# CH569 register map
Vendor: WCH Ltd.; File version: 1.1
Registers are 32-bit, read-write, reset 0x0 unless marked. A register's access mark holds for its fields unless they carry their own. Offsets are from the block's base; [hi:lo] are bit positions; {n}, {i} and the like mark numbered series.

## SYS
Base 0x40001000
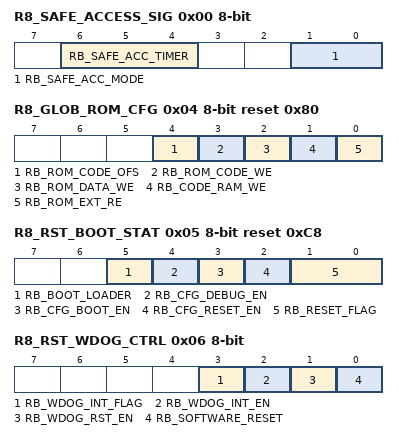
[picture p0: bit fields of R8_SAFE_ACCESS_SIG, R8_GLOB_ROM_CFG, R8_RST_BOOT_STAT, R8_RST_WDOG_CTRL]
0x00 R8_SAFE_ACCESS_SIG 8-bit — safe accessing sign register
  [6:4] RB_SAFE_ACC_TIMER ro — safe accessing timer bit mask
  [1:0] RB_SAFE_ACC_MODE ro — current safe accessing mode
0x01 R8_CHIP_ID 8-bit ro reset 0x69 — chip ID register
  [7:0] R8_CHIP_ID — chip ID
0x02 R8_SAFE_ACCESS_ID 8-bit ro reset 0x2 — safe accessing ID register
  [7:0] R8_SAFE_ACCESS_ID — safe accessing ID
0x03 R8_WDOG_COUNT 8-bit — watch-dog count register
  [7:0] R8_WDOG_COUNT — watch-dog count
0x04 R8_GLOB_ROM_CFG 8-bit access per field reset 0x80 — flash ROM configuration register
  [4] RB_ROM_CODE_OFS rw — Config the start offset address of user code in Flash
  [3] RB_ROM_CODE_WE rw — enable flash ROM code_data area being erase/write
  [2] RB_ROM_DATA_WE rw — enable flash ROM data area being erase/write
  [1] RB_CODE_RAM_WE rw — enable code RAM being write
  [0] RB_ROM_EXT_RE ro — enable flash ROM being read by external programmer
0x05 R8_RST_BOOT_STAT 8-bit ro reset 0xC8 — reset status and boot/debug status
  [5] RB_BOOT_LOADER — indicate boot loader status
  [4] RB_CFG_DEBUG_EN — debug enable status
  [3] RB_CFG_BOOT_EN — boot-loader enable status
  [2] RB_CFG_RESET_EN — manual reset input enable status
  [1:0] RB_RESET_FLAG — recent reset flag
0x06 R8_RST_WDOG_CTRL 8-bit access per field — reset and watch-dog control
  [3] RB_WDOG_INT_FLAG rw — watch-dog timer overflow interrupt flag
  [2] RB_WDOG_INT_EN rw — watch-dog interrupt enable or INT_ID_WDOG interrupt source selection: 0=software interrupt
  [1] RB_WDOG_RST_EN rw — enable watch-dog reset if watch-dog timer overflow: 0=as timer only, 1=enable reset if timer overflow
  [0] RB_SOFTWARE_RESET wo — global software reset
0x07 R8_GLOB_RESET_KEEP 8-bit — value keeper during global reset
0x08 R8_CLK_PLL_DIV 8-bit reset 0x42 — output clock divider from PLL
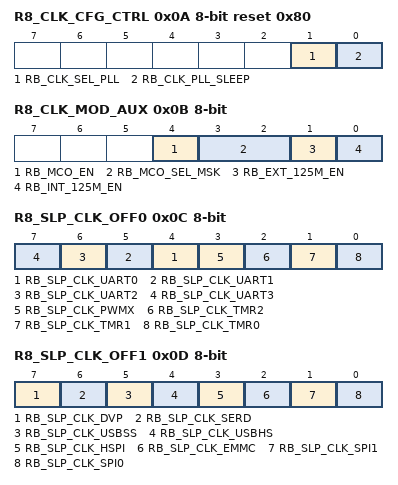
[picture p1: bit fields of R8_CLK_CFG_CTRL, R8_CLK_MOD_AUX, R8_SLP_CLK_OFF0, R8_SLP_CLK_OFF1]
0x0A R8_CLK_CFG_CTRL 8-bit reset 0x80 — clock control
  [1] RB_CLK_SEL_PLL — clock source selection
  [0] RB_CLK_PLL_SLEEP — PLL sleep control
0x0B R8_CLK_MOD_AUX 8-bit — clock mode aux register
  [4] RB_MCO_EN — MCO output enable
  [3:2] RB_MCO_SEL_MSK — MCO output selection
  [1] RB_EXT_125M_EN — clock from pin_PA[16]
  [0] RB_INT_125M_EN — clock from USB_PHY PCLK(125MHz)
0x0C R8_SLP_CLK_OFF0 8-bit — sleep clock off control byte 0
  [n+4] RB_SLP_CLK_UART{n} (n=0..3) — sleep UART{n} clock
  [3] RB_SLP_CLK_PWMX — sleep PWMX clock
  [2] RB_SLP_CLK_TMR2 — sleep TMR2 clock
  [1] RB_SLP_CLK_TMR1 — sleep TMR1 clock
  [0] RB_SLP_CLK_TMR0 — sleep TMR0 clock
0x0D R8_SLP_CLK_OFF1 8-bit access per field — sleep clock off control byte 1
  [7] RB_SLP_CLK_DVP ro — sleep DVP clock
  [6] RB_SLP_CLK_SERD rw — sleep SERD clock
  [5] RB_SLP_CLK_USBSS rw — sleep USBSS clock
  [4] RB_SLP_CLK_USBHS rw — sleep USBHS clock
  [3] RB_SLP_CLK_HSPI rw — sleep HSPI clock
  [2] RB_SLP_CLK_EMMC rw — sleep EMMC clock
  [1] RB_SLP_CLK_SPI1 rw — sleep SPI1 clock
  [0] RB_SLP_CLK_SPI0 rw — sleep SPI0 clock
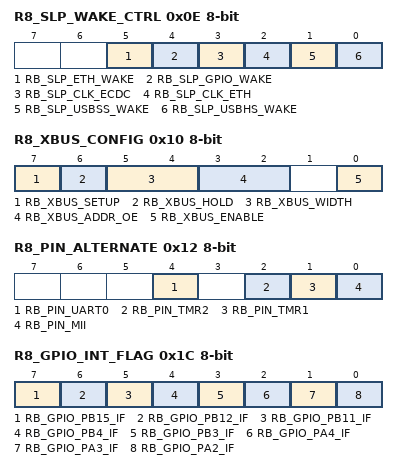
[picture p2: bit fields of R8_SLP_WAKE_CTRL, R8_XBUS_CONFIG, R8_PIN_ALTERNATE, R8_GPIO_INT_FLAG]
0x0E R8_SLP_WAKE_CTRL 8-bit — wake control
  [5] RB_SLP_ETH_WAKE — enable Eth waking
  [4] RB_SLP_GPIO_WAKE — enable GPIO waking
  [3] RB_SLP_CLK_ECDC — sleep ECDC clock
  [2] RB_SLP_CLK_ETH — sleep ETH clock
  [1] RB_SLP_USBSS_WAKE — enable USBSS waking
  [0] RB_SLP_USBHS_WAKE — enable USBHS waking
0x0F R8_SLP_POWER_CTRL 8-bit — power control
  [0] RB_SLP_USBHS_PWRDN — enable USBHS power down
0x10 R8_XBUS_CONFIG 8-bit — external bus configuration
  [7] RB_XBUS_SETUP — external bus setup time
  [6] RB_XBUS_HOLD — external bus hold time
  [5:4] RB_XBUS_WIDTH — external bus access pulse width
  [3:2] RB_XBUS_ADDR_OE — external bus address output enable
  [0] RB_XBUS_ENABLE — external bus enable
0x12 R8_PIN_ALTERNATE 8-bit — alternate pin control
  [4] RB_PIN_UART0 — RXD0/TXD0 alternate pin enable
  [2] RB_PIN_TMR2 — TMR2 alternate pin enable
  [1] RB_PIN_TMR1 — TMR1 alternate pin enable
  [0] RB_PIN_MII — ETH mii interface selection
0x1C R8_GPIO_INT_FLAG 8-bit — GPIO interrupt control
  [7] RB_GPIO_PB15_IF — PB15 pin interrupt flag
  [6] RB_GPIO_PB12_IF — PB12 pin interrupt flag
  [5] RB_GPIO_PB11_IF — PB11 pin interrupt flag
  [4] RB_GPIO_PB4_IF — PB4 pin interrupt flag
  [3] RB_GPIO_PB3_IF — PB3 pin interrupt flag
  [2] RB_GPIO_PA4_IF — PA4 pin interrupt flag
  [1] RB_GPIO_PA3_IF — PA3 pin interrupt flag
  [0] RB_GPIO_PA2_IF — PA2 pin interrupt flag
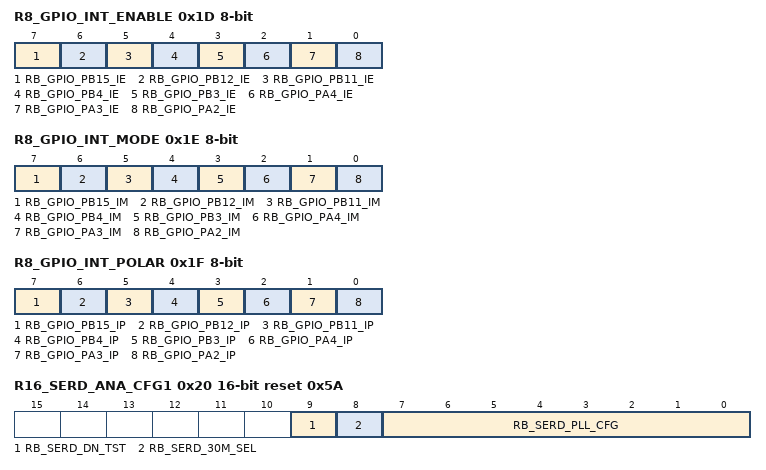
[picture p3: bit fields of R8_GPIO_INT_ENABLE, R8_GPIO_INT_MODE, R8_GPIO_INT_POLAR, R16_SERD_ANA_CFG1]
0x1D R8_GPIO_INT_ENABLE 8-bit — GPIO interrupt enable
  [7] RB_GPIO_PB15_IE — PB15 pin interrupt enable
  [6] RB_GPIO_PB12_IE — PB12 pin interrupt enable
  [5] RB_GPIO_PB11_IE — PB11 pin interrupt enable
  [4] RB_GPIO_PB4_IE — PB4 pin interrupt enable
  [3] RB_GPIO_PB3_IE — PB3 pin interrupt enable
  [2] RB_GPIO_PA4_IE — PA4 pin interrupt enable
  [1] RB_GPIO_PA3_IE — PA3 pin interrupt enable
  [0] RB_GPIO_PA2_IE — PA2 pin interrupt enable
0x1E R8_GPIO_INT_MODE 8-bit — GPIO interrupt mode
  [7] RB_GPIO_PB15_IM — PB15 pin interrupt mode
  [6] RB_GPIO_PB12_IM — PB12 pin interrupt mode
  [5] RB_GPIO_PB11_IM — PB11 pin interrupt mode
  [4] RB_GPIO_PB4_IM — PB4 pin interrupt mode
  [3] RB_GPIO_PB3_IM — PB3 pin interrupt mode
  [2] RB_GPIO_PA4_IM — PA4 pin interrupt mode
  [1] RB_GPIO_PA3_IM — PA3 pin interrupt mode
  [0] RB_GPIO_PA2_IM — PA2 pin interrupt mode
0x1F R8_GPIO_INT_POLAR 8-bit — GPIO interrupt polarity
  [7] RB_GPIO_PB15_IP — PB15 pin interrupt mode
  [6] RB_GPIO_PB12_IP — PB12 pin interrupt mode
  [5] RB_GPIO_PB11_IP — PB11 pin interrupt mode
  [4] RB_GPIO_PB4_IP — PB4 pin interrupt mode
  [3] RB_GPIO_PB3_IP — PB3 pin interrupt mode
  [2] RB_GPIO_PA4_IP — PA4 pin interrupt mode
  [1] RB_GPIO_PA3_IP — PA3 pin interrupt mode
  [0] RB_GPIO_PA2_IP — PA2 pin interrupt mode
0x20 R16_SERD_ANA_CFG1 16-bit reset 0x5A — Serdes Analog parameter configuration1
  [9] RB_SERD_DN_TST — Enable SerDes PHY GXM test pin
  [8] RB_SERD_30M_SEL — SerDes PHY reference clock source seletion
  [7:0] RB_SERD_PLL_CFG — SerDes PHY internal configuration bit
0x24 R32_SERD_ANA_CFG2 reset 0x423015 — Serdes Analog parameter configuration2
  [24:0] RB_SERD_TRX_CFG — Tx and RX parameter setting
0x40 R32_PA_DIR — GPIO PA I/O direction
  [23:0] R32_PA_DIR
0x44 R32_PA_PIN ro — GPIO PA input
  [23:0] R32_PA_PIN
0x48 R32_PA_OUT — GPIO PA output
  [23:0] R32_PA_OUT
0x4C R32_PA_CLR wo — GPIO PA clear output
  [23:0] R32_PA_CLR
0x50 R32_PA_PU — GPIO PA pullup resistance enable
  [23:0] R32_PA_PU
0x54 R32_PA_PD — GPIO PA output open-drain_input pulldown resistance enable
  [23:0] R32_PA_PD
0x58 R32_PA_DRV — GPIO PA driving capability
  [23:0] R32_PA_DRV
0x5C R32_PA_SMT — GPIO PA output slew rate_input schmitt trigger
  [23:0] R32_PA_SMT
0x60 R32_PB_DIR — GPIO PB I/O direction
  [24:0] R32_PB_DIR
0x64 R32_PB_PIN ro — GPIO PB input
  [24:0] R32_PB_PIN
0x68 R32_PB_OUT — GPIO PB output
  [24:0] R32_PB_OUT
0x6C R32_PB_CLR wo — GPIO PB clear output
  [24:0] R32_PB_CLR
0x70 R32_PB_PU — GPIO PB pullup resistance enable
  [24:0] R32_PB_PU
0x74 R32_PB_PD — GPIO PB output open-drain_input pulldown resistance enable
  [24:0] R32_PB_PD
0x78 R32_PB_DRV — GPIO PB driving capability
  [24:0] R32_PB_DRV
0x7C R32_PB_SMT — GPIO PB output slew rate_input schmitt trigger
  [24:0] R32_PB_SMT
